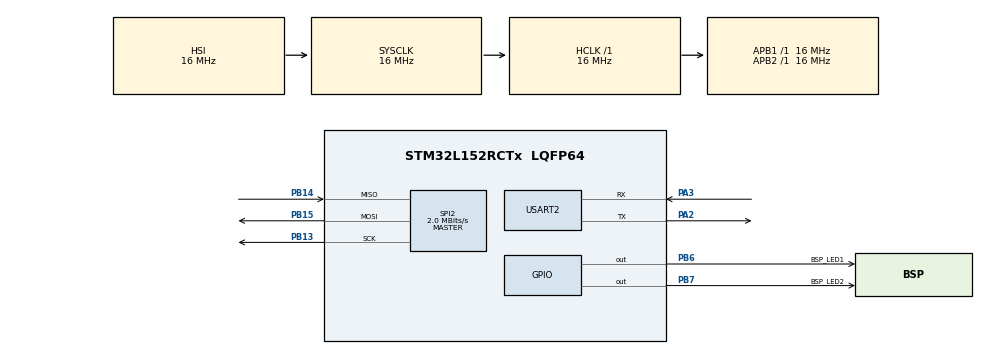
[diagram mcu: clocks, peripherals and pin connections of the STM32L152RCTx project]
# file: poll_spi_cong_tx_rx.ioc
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Mcu.Family=STM32L1
Mcu.Name=STM32L152RCTx
Mcu.Package=LQFP64
NVIC.PriorityGroup=NVIC_PRIORITYGROUP_0
PA2.Mode=Asynchronous
PA2.Signal=USART2_TX
PA3.Mode=Asynchronous
PA3.Signal=USART2_RX
PB13.Mode=Full_Duplex_Master
PB13.Signal=SPI2_SCK
PB14.Mode=Full_Duplex_Master
PB14.Signal=SPI2_MISO
PB15.Mode=Full_Duplex_Master
PB15.Signal=SPI2_MOSI
PB6.GPIO_Label=BSP_LED1
PB6.Signal=GPIO_Output
PB7.GPIO_Label=BSP_LED2
PB7.Signal=GPIO_Output
ProjectManager.HeapSize=0x200
ProjectManager.StackSize=0x400
ProjectManager.TargetToolchain=STM32CubeIDE
RCC.48MHZClocksFreq_Value=48000000
RCC.AHBFreq_Value=16000000
RCC.APB1Freq_Value=16000000
RCC.APB1TimFreq_Value=16000000
RCC.APB2Freq_Value=16000000
RCC.APB2TimFreq_Value=16000000
RCC.HCLKFreq_Value=16000000
RCC.HSE_VALUE=8000000
RCC.HSI_VALUE=16000000
RCC.LSE_VALUE=32768
RCC.MSI_VALUE=2097000
RCC.PLLDIV=RCC_PLL_DIV3
RCC.PLLMUL=RCC_PLL_MUL6
RCC.RTCClockSelectionVirtual=RCC_RTCCLKSOURCE_LSE
RCC.SYSCLKFreq_VALUE=16000000
RCC.SYSCLKSource=RCC_SYSCLKSOURCE_HSI
RCC.USBOutput=48000000
RCC.VCOOutputFreq_Value=96000000
SPI2.BaudRatePrescaler=SPI_BAUDRATEPRESCALER_8
SPI2.CalculateBaudRate=2.0 MBits/s
SPI2.Direction=SPI_DIRECTION_2LINES
SPI2.Mode=SPI_MODE_MASTER
SPI2.VirtualType=VM_MASTER
USART2.VirtualMode=VM_ASYNC
board=STM32L152C-DISCO

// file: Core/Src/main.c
/* USER CODE BEGIN Header */
/**
  ******************************************************************************
  * @file           : main.c
  * @brief          : Main program body
  ******************************************************************************
  * @attention
  *
  * Copyright (c) 2023 STMicroelectronics.
  * All rights reserved.
  *
  * This software is licensed under terms that can be found in the LICENSE file
  * in the root directory of this software component.
  * If no LICENSE file comes with this software, it is provided AS-IS.
  *
  ******************************************************************************
  */
/* USER CODE END Header */
#include "main.h"

/* USER CODE BEGIN Includes */
#include<stdio.h>
/* USER CODE END Includes */

SPI_HandleTypeDef hspi2;

UART_HandleTypeDef huart2;

/* USER CODE BEGIN PV */
uint8_t tx_buff[13]="hirenjadav\r\n";
uint8_t rx_buff[13];

/* USER CODE END PV */

void SystemClock_Config(void);
static void MX_GPIO_Init(void);
static void MX_USART2_UART_Init(void);
static void MX_SPI2_Init(void);

int main(void)
{

  /* MCU Configuration--------------------------------------------------------*/

  /* Reset of all peripherals, Initializes the Flash interface and the Systick. */
  HAL_Init();

  /* Configure the system clock */
  SystemClock_Config();

  /* Initialize all configured peripherals */
  MX_GPIO_Init();
  MX_USART2_UART_Init();
  MX_SPI2_Init();
  /* USER CODE BEGIN 2 */

//this function is use loopback->means mosi to miso in master only to be send data
  HAL_SPI_TransmitReceive(&hspi2, tx_buff, rx_buff, sizeof(tx_buff),1000);
  printf("%s\r\n",rx_buff);

// no use
//if( HAL_SPI_TransmitReceive(&hspi2, tx_buff, rx_buff, sizeof(tx_buff),1000)== HAL_OK)
//{
//	 HAL_SPI_Transmit(&hspi2, rx_buff, 13,1000);
//
//	 printf("%s\r\n",rx_buff);
//}

  /* USER CODE END 2 */

  /* Infinite loop */
  while (1)
  {

  }
}

void SystemClock_Config(void)
{
  RCC_OscInitTypeDef RCC_OscInitStruct = {0};
  RCC_ClkInitTypeDef RCC_ClkInitStruct = {0};

  /** Configure the main internal regulator output voltage
  */
  __HAL_PWR_VOLTAGESCALING_CONFIG(PWR_REGULATOR_VOLTAGE_SCALE1);

  /** Initializes the RCC Oscillators according to the specified parameters
  * in the RCC_OscInitTypeDef structure.
  */
  RCC_OscInitStruct.OscillatorType = RCC_OSCILLATORTYPE_HSI;
  RCC_OscInitStruct.HSIState = RCC_HSI_ON;
  RCC_OscInitStruct.HSICalibrationValue = RCC_HSICALIBRATION_DEFAULT;
  RCC_OscInitStruct.PLL.PLLState = RCC_PLL_NONE;
  if (HAL_RCC_OscConfig(&RCC_OscInitStruct) != HAL_OK)
  {
    Error_Handler();
  }

  /** Initializes the CPU, AHB and APB buses clocks
  */
  RCC_ClkInitStruct.ClockType = RCC_CLOCKTYPE_HCLK|RCC_CLOCKTYPE_SYSCLK
                              |RCC_CLOCKTYPE_PCLK1|RCC_CLOCKTYPE_PCLK2;
  RCC_ClkInitStruct.SYSCLKSource = RCC_SYSCLKSOURCE_HSI;
  RCC_ClkInitStruct.AHBCLKDivider = RCC_SYSCLK_DIV1;
  RCC_ClkInitStruct.APB1CLKDivider = RCC_HCLK_DIV1;
  RCC_ClkInitStruct.APB2CLKDivider = RCC_HCLK_DIV1;

  if (HAL_RCC_ClockConfig(&RCC_ClkInitStruct, FLASH_LATENCY_0) != HAL_OK)
  {
    Error_Handler();
  }
}

static void MX_SPI2_Init(void)
{

  /* SPI2 parameter configuration*/
  hspi2.Instance = SPI2;
  hspi2.Init.Mode = SPI_MODE_MASTER;
  hspi2.Init.Direction = SPI_DIRECTION_2LINES;
  hspi2.Init.DataSize = SPI_DATASIZE_8BIT;
  hspi2.Init.CLKPolarity = SPI_POLARITY_LOW;
  hspi2.Init.CLKPhase = SPI_PHASE_1EDGE;
  hspi2.Init.NSS = SPI_NSS_SOFT;
  hspi2.Init.BaudRatePrescaler = SPI_BAUDRATEPRESCALER_8;
  hspi2.Init.FirstBit = SPI_FIRSTBIT_MSB;
  hspi2.Init.TIMode = SPI_TIMODE_DISABLE;
  hspi2.Init.CRCCalculation = SPI_CRCCALCULATION_DISABLE;
  hspi2.Init.CRCPolynomial = 10;
  if (HAL_SPI_Init(&hspi2) != HAL_OK)
  {
    Error_Handler();
  }

}

static void MX_USART2_UART_Init(void)
{

  huart2.Instance = USART2;
  huart2.Init.BaudRate = 115200;
  huart2.Init.WordLength = UART_WORDLENGTH_8B;
  huart2.Init.StopBits = UART_STOPBITS_1;
  huart2.Init.Parity = UART_PARITY_NONE;
  huart2.Init.Mode = UART_MODE_TX_RX;
  huart2.Init.HwFlowCtl = UART_HWCONTROL_NONE;
  huart2.Init.OverSampling = UART_OVERSAMPLING_16;
  if (HAL_UART_Init(&huart2) != HAL_OK)
  {
    Error_Handler();
  }

}

static void MX_GPIO_Init(void)
{
  GPIO_InitTypeDef GPIO_InitStruct = {0};

  /* GPIO Ports Clock Enable */
  __HAL_RCC_GPIOA_CLK_ENABLE();
  __HAL_RCC_GPIOB_CLK_ENABLE();

  /*Configure GPIO pin Output Level */
  HAL_GPIO_WritePin(GPIOB, BSP_LED1_Pin|BSP_LED2_Pin, GPIO_PIN_RESET);

  /*Configure GPIO pins : BSP_LED1_Pin BSP_LED2_Pin */
  GPIO_InitStruct.Pin = BSP_LED1_Pin|BSP_LED2_Pin;
  GPIO_InitStruct.Mode = GPIO_MODE_OUTPUT_PP;
  GPIO_InitStruct.Pull = GPIO_NOPULL;
  GPIO_InitStruct.Speed = GPIO_SPEED_FREQ_LOW;
  HAL_GPIO_Init(GPIOB, &GPIO_InitStruct);

}

void Error_Handler(void)
{
  __disable_irq();
  while (1)
  {
  }
}
